# STM32H743 register map
File version: 2.4
CPU: CM7 r0p1, little endian, MPU, FPU, 4 interrupt priority bits
Registers are 32-bit, read-write, reset 0x0 unless marked. A register's access mark holds for its fields unless they carry their own. Offsets are from the block's base; [hi:lo] are bit positions; {n}, {i} and the like mark numbered series; 'fields as' and 'values as' point back to an identical list.

## MDIOS — 管理数据输入/输出从机接口
Base 0x40009400
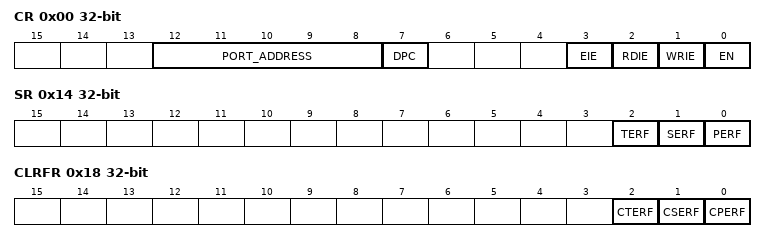
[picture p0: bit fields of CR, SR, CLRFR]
0x00 CR — MDIOS 配置寄存器
  [12:8] PORT_ADDRESS — 从机地址
  [7] DPC — 禁止前导码检查
  [3] EIE — 错误中断使能
  [2] RDIE — 寄存器读中断使能
  [1] WRIE — 寄存器写中断使能
  [0] EN — 外设使能
0x04 WRFR ro — MDIOS 写标志寄存器
  [31:0] WRF — MDIO 寄存器 0 至 31 的写标志
0x08 CWRFR — MDIOS 清除写标志寄存器
  [31:0] CWRF — 清除写标志
0x0C RDFR ro — MDIOS 读标志寄存器
  [31:0] RDF — MDIO 寄存器 0 至 31 的读标志
0x10 CRDFR — MDIOS 清除读标志寄存器
  [31:0] CRDF — 清除读标志
0x14 SR ro — MDIOS 状态寄存器
  [2] TERF — 周转错误标志
  [1] SERF — 起始错误标志
  [0] PERF — 前导码错误标志
0x18 CLRFR — MDIOS 标志清除寄存器
  [2] CTERF — 清除周转错误标志
  [1] CSERF — 清除起始错误标志
  [0] CPERF — 清除前导码错误标志
{0x1C+4i} DINR{i} ro (i=0..31) — MDIOS 输入数据寄存器 {i}
  [15:0] DIN{i} — 写帧期间从 MDIO 主机接收的输入数据
{0x9C+4i} DOUTR{i} (i=0..31) — MDIOS 输出数据寄存器 {i}
  [15:0] DOUT{i} — 读帧期间发送至 MDIO 主机的输出数据

## OPAMP — 运算放大器
Base 0x40009000
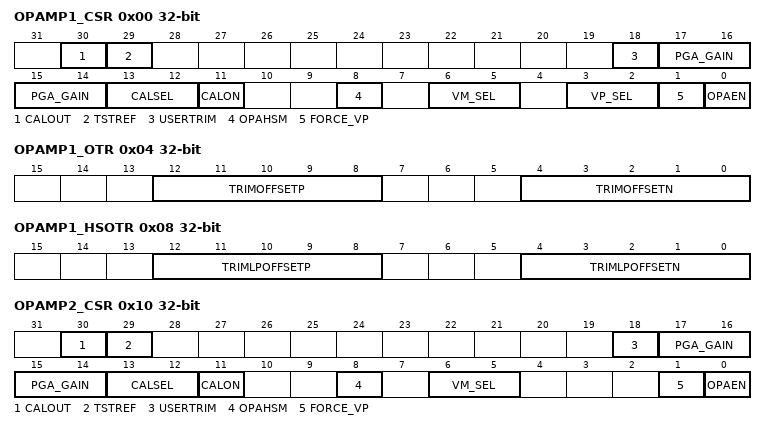
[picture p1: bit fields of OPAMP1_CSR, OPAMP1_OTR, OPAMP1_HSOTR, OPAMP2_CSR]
0x00 OPAMP1_CSR — OPAMP1 控制/状态寄存器
  [30] CALOUT — 运算放大器校准输出
  [29] TSTREF — OPAMP 校准参考电压输出控制（保留用于测试）
  [18] USERTRIM — 用户微调使能
  [17:14] PGA_GAIN — 用于在 AOP 偏移微调值与 AOP 偏移之间切换
  [13:12] CALSEL — 校准选择
  [11] CALON — 校准模式使能
  [8] OPAHSM — 运算放大器高速模式
  [6:5] VM_SEL — 反相输入端选择
  [3:2] VP_SEL — 运算放大器 PGA 模式选择
  [1] FORCE_VP — 强制在 VP 端施加内部参考电压（保留用于测试）
  [0] OPAEN — 运算放大器使能
0x04 OPAMP1_OTR — OPAMP1 正常模式偏移微调寄存器
  [12:8] TRIMOFFSETP — PMOS 差分对微调值
  [4:0] TRIMOFFSETN — NMOS 差分对微调值
0x08 OPAMP1_HSOTR — OPAMP1 低功耗模式偏移微调寄存器
  [12:8] TRIMLPOFFSETP — PMOS 差分对微调值
  [4:0] TRIMLPOFFSETN — NMOS 差分对微调值
0x10 OPAMP2_CSR — OPAMP2 控制/状态寄存器
  [30] CALOUT — 运算放大器校准输出
  [29] TSTREF — OPAMP 校准参考电压输出控制（保留用于测试）
  [18] USERTRIM — 用户微调使能
  [17:14] PGA_GAIN — 运算放大器可编程增益值
  [13:12] CALSEL — 校准选择
  [11] CALON — 校准模式使能
  [8] OPAHSM — 运算放大器高速模式
  [6:5] VM_SEL — 反相输入端选择
  [1] FORCE_VP — 强制在 VP 端施加内部参考电压（保留用于测试）
  [0] OPAEN — 运算放大器使能
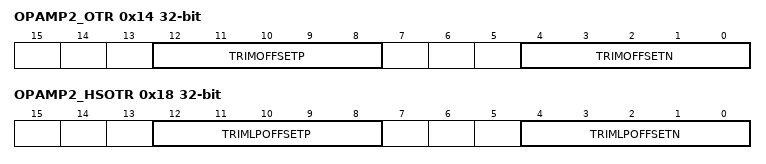
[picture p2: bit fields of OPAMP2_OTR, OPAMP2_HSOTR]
0x14 OPAMP2_OTR — OPAMP2 正常模式偏移微调寄存器
  [12:8] TRIMOFFSETP — PMOS 差分对微调值
  [4:0] TRIMOFFSETN — NMOS 差分对微调值
0x18 OPAMP2_HSOTR — OPAMP2 低功耗模式偏移微调寄存器
  fields as OPAMP1_HSOTR

## SWPMI — 单线协议主接口
Base 0x40008800
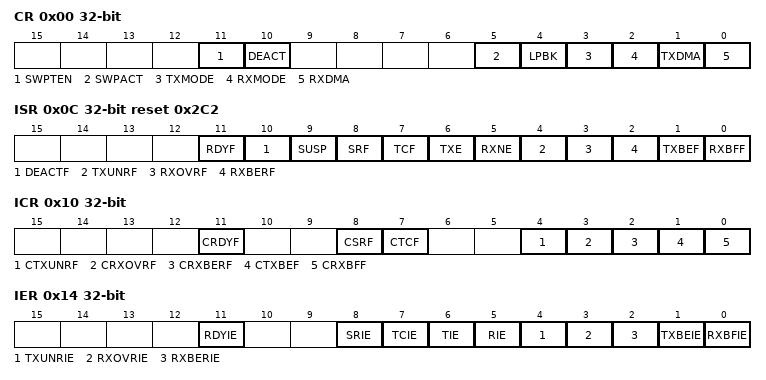
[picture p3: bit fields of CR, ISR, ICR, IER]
0x00 CR — SWPMI 配置/控制寄存器
  [11] SWPTEN — 单线协议主收发器使能
  [10] DEACT — 单线协议主接口去激活
  [5] SWPACT — 单线协议主接口激活
  [4] LPBK — 环回模式使能
  [3] TXMODE — 发送缓冲模式
  [2] RXMODE — 接收缓冲模式
  [1] TXDMA — 发送 DMA 使能
  [0] RXDMA — 接收 DMA 使能
0x04 BRR reset 0x1 — SWPMI 波特率寄存器
  [7:0] BR — 波特率预分频器
0x0C ISR ro reset 0x2C2 — SWPMI 中断与状态寄存器
  [11] RDYF — 收发器就绪标志
  [10] DEACTF — 已去激活标志
  [9] SUSP — 挂起标志
  [8] SRF — 从机恢复标志
  [7] TCF — 传输完成标志
  [6] TXE — 发送数据寄存器空
  [5] RXNE — 接收数据寄存器非空
  [4] TXUNRF — 发送欠载错误标志
  [3] RXOVRF — 接收溢出错误标志
  [2] RXBERF — 接收 CRC 错误标志
  [1] TXBEF — 发送缓冲器空标志
  [0] RXBFF — 接收缓冲器满标志
0x10 ICR wo — SWPMI 中断标志清除寄存器
  [11] CRDYF — 清除收发器就绪标志
  [8] CSRF — 清除从机恢复标志
  [7] CTCF — 清除传输完成标志
  [4] CTXUNRF — 清除发送欠载错误标志
  [3] CRXOVRF — 清除接收溢出错误标志
  [2] CRXBERF — 清除接收 CRC 错误标志
  [1] CTXBEF — 清除发送缓冲器空标志
  [0] CRXBFF — 清除接收缓冲器满标志
0x14 IER — SWPMI 中断使能寄存器
  [11] RDYIE — 收发器就绪中断使能
  [8] SRIE — 从机恢复中断使能
  [7] TCIE — 发送完成中断使能
  [6] TIE — 发送中断使能
  [5] RIE — 接收中断使能
  [4] TXUNRIE — 发送欠载错误中断使能
  [3] RXOVRIE — 接收溢出错误中断使能
  [2] RXBERIE — 接收 CRC 错误中断使能
  [1] TXBEIE — 发送缓冲器空中断使能
  [0] RXBFIE — 接收缓冲器满中断使能
0x18 RFL ro — SWPMI 接收帧长度寄存器
  [4:0] RFL — 接收帧长度
0x1C TDR wo — SWPMI 发送数据寄存器
  [31:0] TD — 发送数据
0x20 RDR ro — SWPMI 接收数据寄存器
  [31:0] RD — 接收数据
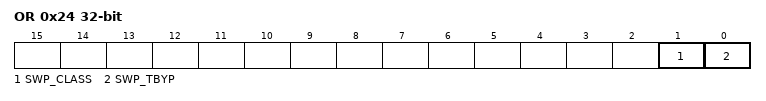
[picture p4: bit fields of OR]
0x24 OR — SWPMI 选项寄存器
  [1] SWP_CLASS — SWP 类别选择
  [0] SWP_TBYP — SWP 收发器旁路

## TIM2 — 通用定时器
Base 0x40000000
Same registers: TIM3 0x40000400, TIM4 0x40000800, TIM5 0x40000C00, TIM12 0x40001800, TIM13 0x40001C00, TIM14 0x40002000
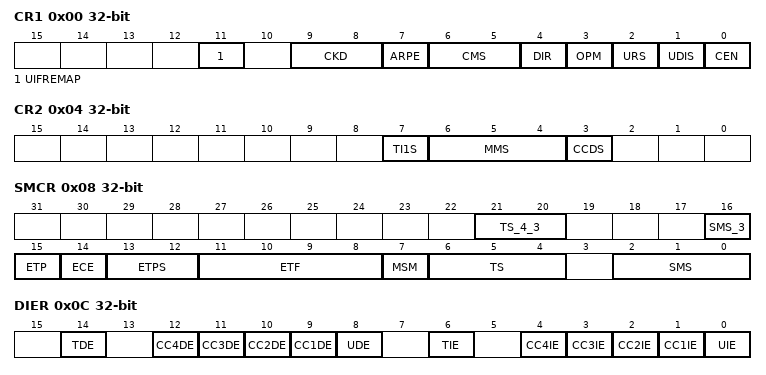
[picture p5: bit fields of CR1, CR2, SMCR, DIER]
0x00 CR1 — 控制寄存器 1
  [11] UIFREMAP — UIF 状态位重映射
  [9:8] CKD — 时钟分频
  [7] ARPE — 自动重装载预装载使能
  [6:5] CMS — 中心对齐模式选择
  [4] DIR — 计数方向
  [3] OPM — 单脉冲模式
  [2] URS — 更新请求源
  [1] UDIS — 更新禁止
  [0] CEN — 计数器使能
0x04 CR2 — 控制寄存器 2
  [7] TI1S — TI1 选择
  [6:4] MMS — 主模式选择
  [3] CCDS — 捕获/比较 DMA 选择
0x08 SMCR — 从模式控制寄存器
  [21:20] TS_4_3 — 触发选择
  [16] SMS_3 — 从模式选择 - 位 3
  [15] ETP — 外部触发极性
  [14] ECE — 外部时钟使能
  [13:12] ETPS — 外部触发预分频器
  [11:8] ETF — 外部触发滤波器
  [7] MSM — 主/从模式
  [6:4] TS — 触发选择
  [2:0] SMS — 从模式选择
0x0C DIER — DMA/中断使能寄存器
  [14] TDE — 触发 DMA 请求使能
  [n+8] CC{n}DE (n=1..4) — 捕获/比较 {n} DMA 请求使能
  [8] UDE — 更新 DMA 请求使能
  [6] TIE — 触发中断使能
  [n] CC{n}IE (n=1..4) — 捕获/比较 {n} 中断使能
  [0] UIE — 更新中断使能
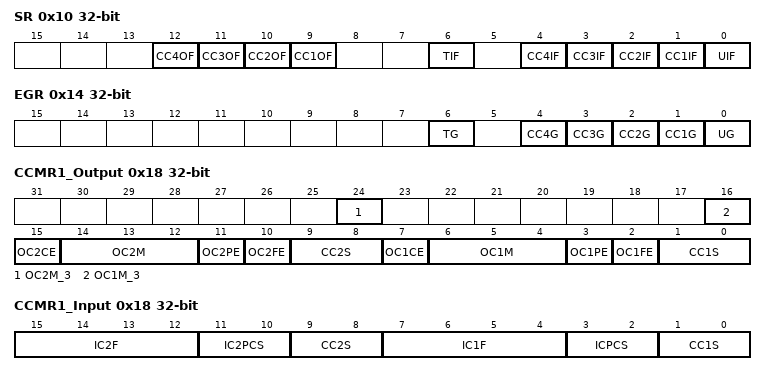
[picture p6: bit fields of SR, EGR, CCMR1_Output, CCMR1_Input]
0x10 SR — 状态寄存器
  [n+8] CC{n}OF (n=1..4) — 捕获/比较 {n} 重复捕获标志
  [6] TIF — 触发中断标志
  [n] CC{n}IF (n=1..4) — 捕获/比较 {n} 中断标志
  [0] UIF — 更新中断标志
0x14 EGR wo — 事件生成寄存器
  [6] TG — 触发生成
  [n] CC{n}G (n=1..4) — 捕获/比较 {n} 生成
  [0] UG — 更新生成
0x18 CCMR1_Output — 捕获/比较模式寄存器 1（输出模式）
  [24] OC2M_3 — 输出比较 2 模式 - 位 3
  [16] OC1M_3 — 输出比较 1 模式 - 位 3
  [15] OC2CE — 输出比较 2 清零使能
  [14:12] OC2M — 输出比较 2 模式
  [11] OC2PE — 输出比较 2 预装载使能
  [10] OC2FE — 输出比较 2 快速使能
  [9:8] CC2S — 捕获/比较 2 选择
  [7] OC1CE — 输出比较 1 清零使能
  [6:4] OC1M — 输出比较 1 模式
  [3] OC1PE — 输出比较 1 预装载使能
  [2] OC1FE — 输出比较 1 快速使能
  [1:0] CC1S — 捕获/比较 1 选择
0x18 CCMR1_Input (alternate view of CCMR1_Output) — 捕获/比较模式寄存器 1（输入模式）
  [15:12] IC2F — 输入捕获 2 滤波器
  [11:10] IC2PCS — 输入捕获 2 预分频器
  [9:8] CC2S — 捕获/比较 2 选择
  [7:4] IC1F — 输入捕获 1 滤波器
  [3:2] ICPCS — 输入捕获 1 预分频器
  [1:0] CC1S — 捕获/比较 1 选择
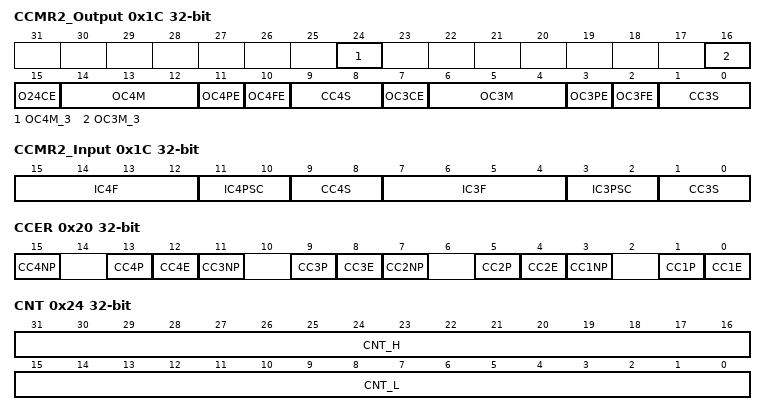
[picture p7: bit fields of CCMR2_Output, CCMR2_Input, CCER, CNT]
0x1C CCMR2_Output — 捕获/比较模式寄存器 2（输出模式）
  [24] OC4M_3 — 输出比较 4 模式 - 位 3
  [16] OC3M_3 — 输出比较 3 模式 - 位 3
  [15] O24CE — 输出比较 2/4 清零使能
  [14:12] OC4M — 输出比较 4 模式
  [11] OC4PE — 输出比较 4 预装载使能
  [10] OC4FE — 输出比较 4 快速使能
  [9:8] CC4S — 捕获/比较 4 选择
  [7] OC3CE — 输出比较 3 清零使能
  [6:4] OC3M — 输出比较 3 模式
  [3] OC3PE — 输出比较 3 预装载使能
  [2] OC3FE — 输出比较 3 快速使能
  [1:0] CC3S — 捕获/比较 3 选择
0x1C CCMR2_Input (alternate view of CCMR2_Output) — 捕获/比较模式寄存器 2（输入模式）
  [15:12] IC4F — 输入捕获 4 滤波器
  [11:10] IC4PSC — 输入捕获 4 预分频器
  [9:8] CC4S — 捕获/比较 4 选择
  [7:4] IC3F — 输入捕获 3 滤波器
  [3:2] IC3PSC — 输入捕获 3 预分频器
  [1:0] CC3S — 捕获/比较 3 选择
0x20 CCER — 捕获/比较使能寄存器
  [4n-1] CC{n}NP (n=1..4) — 捕获/比较 {n} 互补输出极性
  [4n-3] CC{n}P (n=1..4) — 捕获/比较 {n} 输出极性
  [4n-4] CC{n}E (n=1..4) — 捕获/比较 {n} 输出使能
0x24 CNT — 计数器
  [31:16] CNT_H — 计数器高 16 位值
  [15:0] CNT_L — 计数器低 16 位值
0x28 PSC — 预分频器
  [15:0] PSC — 预分频器值
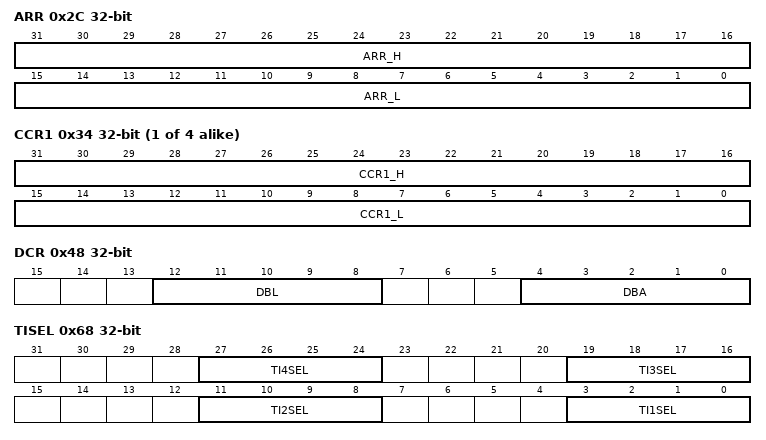
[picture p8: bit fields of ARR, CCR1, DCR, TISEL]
0x2C ARR — 自动重装载寄存器
  [31:16] ARR_H — 自动重装载高 16 位值
  [15:0] ARR_L — 自动重装载低 16 位值
{0x30+4i} CCR{i} (i=1..4) — 捕获/比较寄存器 {i}
  [31:16] CCR{i}_H — 捕获/比较 {i} 高 16 位值
  [15:0] CCR{i}_L — 捕获/比较 {i} 低 16 位值
0x48 DCR — DMA 控制寄存器
  [12:8] DBL — DMA 突发长度
  [4:0] DBA — DMA 基地址
0x4C DMAR — DMA 全传输地址寄存器
  [15:0] DMAB — DMA 突发访问寄存器
0x60 AF1 — TIM 复用功能选项寄存器 1
  [17:14] ETRSEL — ETR 源选择
0x68 TISEL — TIM 定时器输入选择寄存器
  [8n-5:8n-8] TI{n}SEL (n=1..4) — TI{n}[0] 至 TI{n}[15] 输入选择

## TIM6 — 基本定时器
Base 0x40001000
Same registers: TIM7 0x40001400
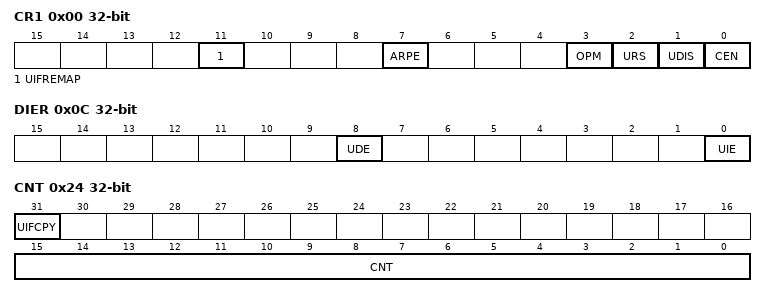
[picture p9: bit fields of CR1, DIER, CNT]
0x00 CR1 — 控制寄存器 1
  [11] UIFREMAP — UIF 状态位重映射
  [7] ARPE — 自动重载预装载使能
  [3] OPM — 单脉冲模式
  [2] URS — 更新请求源
  [1] UDIS — 更新禁用
  [0] CEN — 计数器使能
0x04 CR2 — 控制寄存器 2
  [6:4] MMS — 主模式选择
0x0C DIER — DMA/中断使能寄存器
  [8] UDE — 更新 DMA 请求使能
  [0] UIE — 更新中断使能
0x10 SR — 状态寄存器
  [0] UIF — 更新中断标志
0x14 EGR wo — 事件生成寄存器
  [0] UG — 更新事件生成
0x24 CNT — 计数器
  [31] UIFCPY — UIF 复制
  [15:0] CNT — 计数器低位值
0x28 PSC — 预分频器
  [15:0] PSC — 预分频器值
0x2C ARR — 自动重载寄存器
  [15:0] ARR — 自动重载低位值

## DBGMCU — 微控制器调试单元
Base 0x5C001000
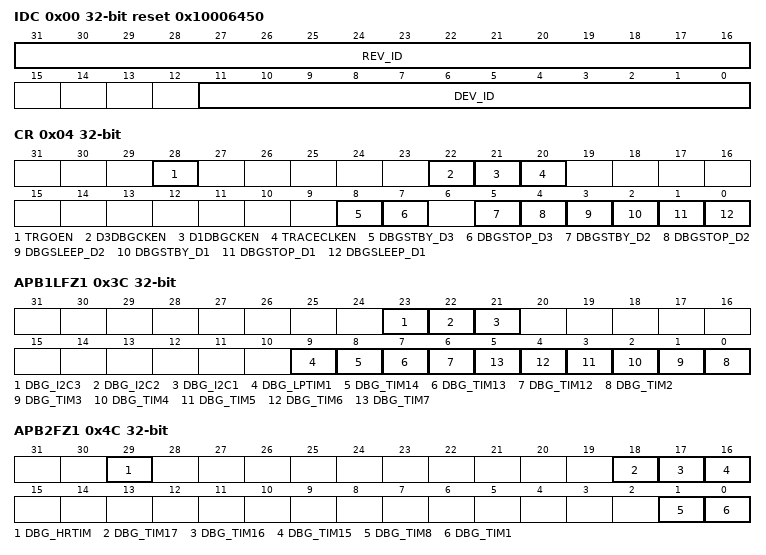
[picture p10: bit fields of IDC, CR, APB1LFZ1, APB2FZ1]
0x00 IDC ro reset 0x10006450 — DBGMCU 身份识别码寄存器
  [31:16] REV_ID — 版本号
  [11:0] DEV_ID — 设备 ID
0x04 CR — DBGMCU 配置寄存器
  [28] TRGOEN — 外部触发输出使能
  [22] D3DBGCKEN — D3 调试时钟使能
  [21] D1DBGCKEN — D1 调试时钟使能
  [20] TRACECLKEN — 跟踪端口时钟使能
  [8] DBGSTBY_D3 — 允许在 D3 待机模式下调试
  [7] DBGSTOP_D3 — 允许在 D3 停止模式下调试
  [5] DBGSTBY_D2 — 允许在待机模式下调试 D2 域
  [4] DBGSTOP_D2 — 允许在停止模式下调试 D2 域
  [3] DBGSLEEP_D2 — 允许在睡眠模式下调试 D2 域
  [2] DBGSTBY_D1 — 允许在待机模式下调试 D1 域
  [1] DBGSTOP_D1 — 允许在停止模式下调试 D1 域
  [0] DBGSLEEP_D1 — 允许在睡眠模式下调试 D1 域
0x34 APB3FZ1 — DBGMCU APB3 外设冻结寄存器
  [6] WWDG1 — 调试时暂停 WWDG1
0x3C APB1LFZ1 — DBGMCU APB1L 外设冻结寄存器
  [23] DBG_I2C3 — 调试时暂停 I2C3 SMBUS 超时
  [22] DBG_I2C2 — 调试时暂停 I2C2 SMBUS 超时
  [21] DBG_I2C1 — 调试时暂停 I2C1 SMBUS 超时
  [9] DBG_LPTIM1 — 调试时暂停 LPTIM1
  [8] DBG_TIM14 — 调试时暂停 TIM14
  [7] DBG_TIM13 — 调试时暂停 TIM13
  [6] DBG_TIM12 — 调试时暂停 TIM12
  [n-2] DBG_TIM{n} (n=2..7) — 调试时暂停 TIM{n}
0x4C APB2FZ1 — DBGMCU APB2 外设冻结寄存器
  [29] DBG_HRTIM — 调试时暂停 HRTIM
  [18] DBG_TIM17 — 调试时暂停 TIM17
  [17] DBG_TIM16 — 调试时暂停 TIM16
  [16] DBG_TIM15 — 调试时暂停 TIM15
  [1] DBG_TIM8 — 调试时暂停 TIM8
  [0] DBG_TIM1 — 调试时暂停 TIM1
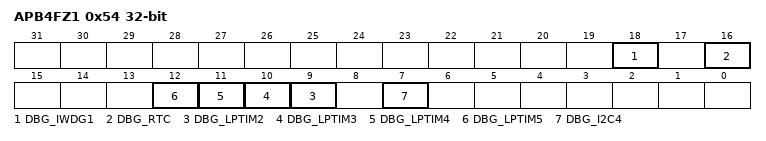
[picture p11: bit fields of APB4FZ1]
0x54 APB4FZ1 — DBGMCU APB4 外设冻结寄存器
  [18] DBG_IWDG1 — 调试时暂停 D1 独立看门狗
  [16] DBG_RTC — 调试时暂停 RTC
  [n+7] DBG_LPTIM{n} (n=2..5) — 调试时暂停 LPTIM{n}
  [7] DBG_I2C4 — 调试时暂停 I2C4 SMBUS 超时
